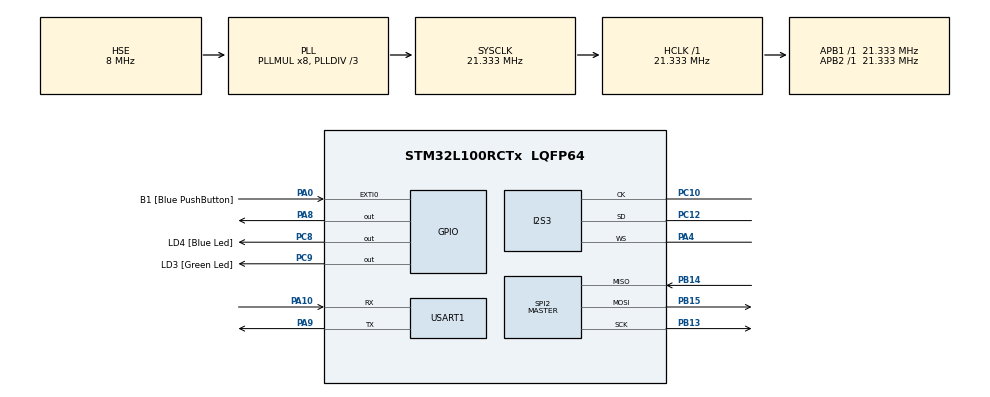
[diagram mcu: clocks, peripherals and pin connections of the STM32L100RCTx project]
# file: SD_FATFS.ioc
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Dma.Request0=USART1_TX
Dma.USART1_TX.0.Direction=DMA_MEMORY_TO_PERIPH
Dma.USART1_TX.0.Instance=DMA1_Channel4
Dma.USART1_TX.0.MemDataAlignment=DMA_MDATAALIGN_BYTE
Dma.USART1_TX.0.MemInc=DMA_MINC_ENABLE
Dma.USART1_TX.0.Mode=DMA_NORMAL
Dma.USART1_TX.0.PeriphDataAlignment=DMA_PDATAALIGN_BYTE
Dma.USART1_TX.0.PeriphInc=DMA_PINC_DISABLE
Dma.USART1_TX.0.Priority=DMA_PRIORITY_LOW
FATFS._MAX_SS=4096
FATFS._USE_LFN=1
I2S3.AudioFreq=I2S_AUDIOFREQ_44K
I2S3.ErrorAudioFreq=1.0 %
I2S3.FullDuplexMode=I2S_FULLDUPLEXMODE_DISABLE
I2S3.Instance=SPI$Index
I2S3.RealAudioFreq=44.444 KHz
I2S3.VirtualMode=I2S_MODE_MASTER
Mcu.Family=STM32L1
Mcu.Name=STM32L100RCTx
Mcu.Package=LQFP64
NVIC.DMA1_Channel4_IRQn=true\:0\:0\:false\:false\:true\:false
NVIC.PriorityGroup=NVIC_PRIORITYGROUP_0
NVIC.TIM2_IRQn=true\:0\:0\:false\:false\:true\:true
NVIC.USART1_IRQn=true\:0\:0\:false\:false\:true\:true
PA0-WKUP1.GPIO_Label=B1 [Blue PushButton]
PA0-WKUP1.GPIO_ModeDefaultEXTI=GPIO_MODE_EVT_RISING
PA0-WKUP1.Signal=GPXTI0
PA10.Mode=Asynchronous
PA10.Signal=USART1_RX
PA13.GPIO_Label=SWDIO
PA13.Mode=Serial_Wire
PA13.Signal=SYS_JTMS-SWDIO
PA14.GPIO_Label=SWCLK
PA14.Mode=Serial_Wire
PA14.Signal=SYS_JTCK-SWCLK
PA4.Mode=Half_Duplex_Master
PA4.Signal=I2S3_WS
PA8.GPIO_Speed=GPIO_SPEED_FREQ_HIGH
PA8.Signal=GPIO_Output
PA9.Mode=Asynchronous
PA9.Signal=USART1_TX
PB13.Mode=Full_Duplex_Master
PB13.Signal=SPI2_SCK
PB14.Mode=Full_Duplex_Master
PB14.Signal=SPI2_MISO
PB15.Mode=Full_Duplex_Master
PB15.Signal=SPI2_MOSI
PB3.GPIO_Label=SWO
PB3.Signal=SYS_JTDO-TRACESWO
PC10.Mode=Half_Duplex_Master
PC10.Signal=I2S3_CK
PC12.Mode=Half_Duplex_Master
PC12.Signal=I2S3_SD
PC14-OSC32_IN.GPIO_Label=PC14-OSC32_IN
PC14-OSC32_IN.Signal=RCC_OSC32_IN
PC15-OSC32_OUT.GPIO_Label=PC15-OSC32_OUT
PC15-OSC32_OUT.Signal=RCC_OSC32_OUT
PC8.GPIO_Label=LD4 [Blue Led]
PC8.Signal=GPIO_Output
PC9.GPIO_Label=LD3 [Green Led]
PC9.Signal=GPIO_Output
PH0-OSC_IN.GPIO_Label=PH0-OSC_IN
PH0-OSC_IN.Mode=HSE-External-Clock-Source
PH0-OSC_IN.Signal=RCC_OSC_IN
PH1-OSC_OUT.GPIO_Label=PH1-OSC_OUT
PH1-OSC_OUT.Signal=RCC_OSC_OUT
ProjectManager.HeapSize=0x200
ProjectManager.StackSize=0x400
ProjectManager.TargetToolchain=SW4STM32
RCC.48MHZClocksFreq_Value=32000000
RCC.AHBFreq_Value=21333333.333333332
RCC.APB1Freq_Value=21333333.333333332
RCC.APB1TimFreq_Value=21333333.333333332
RCC.APB2Freq_Value=21333333.333333332
RCC.APB2TimFreq_Value=21333333.333333332
RCC.HCLKFreq_Value=21333333.333333332
RCC.HSE_VALUE=8000000
RCC.HSI_VALUE=16000000
RCC.LSEState=RCC_LSE_ON
RCC.LSE_VALUE=32768
RCC.MSI_VALUE=2097000
RCC.PLLDIV=RCC_PLL_DIV3
RCC.PLLMUL=RCC_PLL_MUL8
RCC.PLLSourceVirtual=RCC_PLLSOURCE_HSE
RCC.RTCClockSelectionVirtual=RCC_RTCCLKSOURCE_LSE
RCC.SYSCLKFreq_VALUE=21333333.333333332
RCC.SYSCLKSource=RCC_SYSCLKSOURCE_PLLCLK
RCC.USBOutput=48000000
RCC.VCOOutputFreq_Value=64000000
SPI2.BaudRatePrescaler=SPI_BAUDRATEPRESCALER_2
SPI2.CalculateBaudRate=10.666666 MBits/s
SPI2.Direction=SPI_DIRECTION_2LINES
SPI2.Mode=SPI_MODE_MASTER
SPI2.VirtualType=VM_MASTER
TIM2.Period=10
TIM2.Prescaler=39999
USART1.VirtualMode=VM_ASYNC
VP_FATFS_VS_Generic.Mode=User_defined
VP_TIM2_VS_ClockSourceINT.Mode=Internal
board=32L100CDISCOVERY

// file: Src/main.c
/* USER CODE BEGIN Header */
/**
 ******************************************************************************
 * @file           : main.c
 * @brief          : Main program body
 ******************************************************************************
 * This notice applies to any and all portions of this file
 * that are not between comment pairs USER CODE BEGIN and
 * USER CODE END. Other portions of this file, whether
 * inserted by the user or by software development tools
 * are owned by their respective copyright owners.
 *
 * Copyright (c) 2018 STMicroelectronics International N.V.
 * All rights reserved.
 *
 * Redistribution and use in source and binary forms, with or without
 * modification, are permitted, provided that the following conditions are met:
 *
 * 1. Redistribution of source code must retain the above copyright notice,
 *    this list of conditions and the following disclaimer.
 * 2. Redistributions in binary form must reproduce the above copyright notice,
 *    this list of conditions and the following disclaimer in the documentation
 *    and/or other materials provided with the distribution.
 * 3. Neither the name of STMicroelectronics nor the names of other
 *    contributors to this software may be used to endorse or promote products
 *    derived from this software without specific written permission.
 * 4. This software, including modifications and/or derivative works of this
 *    software, must execute solely and exclusively on microcontroller or
 *    microprocessor devices manufactured by or for STMicroelectronics.
 * 5. Redistribution and use of this software other than as permitted under
 *    this license is void and will automatically terminate your rights under
 *    this license.
 *
 * THIS SOFTWARE IS PROVIDED BY STMICROELECTRONICS AND CONTRIBUTORS "AS IS"
 * AND ANY EXPRESS, IMPLIED OR STATUTORY WARRANTIES, INCLUDING, BUT NOT
 * LIMITED TO, THE IMPLIED WARRANTIES OF MERCHANTABILITY, FITNESS FOR A
 * PARTICULAR PURPOSE AND NON-INFRINGEMENT OF THIRD PARTY INTELLECTUAL PROPERTY
 * RIGHTS ARE DISCLAIMED TO THE FULLEST EXTENT PERMITTED BY LAW. IN NO EVENT
 * SHALL STMICROELECTRONICS OR CONTRIBUTORS BE LIABLE FOR ANY DIRECT, INDIRECT,
 * INCIDENTAL, SPECIAL, EXEMPLARY, OR CONSEQUENTIAL DAMAGES (INCLUDING, BUT NOT
 * LIMITED TO, PROCUREMENT OF SUBSTITUTE GOODS OR SERVICES; LOSS OF USE, DATA,
 * OR PROFITS; OR BUSINESS INTERRUPTION) HOWEVER CAUSED AND ON ANY THEORY OF
 * LIABILITY, WHETHER IN CONTRACT, STRICT LIABILITY, OR TORT (INCLUDING
 * NEGLIGENCE OR OTHERWISE) ARISING IN ANY WAY OUT OF THE USE OF THIS SOFTWARE,
 * EVEN IF ADVISED OF THE POSSIBILITY OF SUCH DAMAGE.
 *
 ******************************************************************************
 */
/* USER CODE END Header */

#include "main.h"
#include "fatfs.h"

/* USER CODE BEGIN Includes */
#include "sd.h"
/* USER CODE END Includes */

I2S_HandleTypeDef hi2s3;

SPI_HandleTypeDef hspi2;

TIM_HandleTypeDef htim2;

UART_HandleTypeDef huart1;
DMA_HandleTypeDef hdma_usart1_tx;

/* USER CODE BEGIN PV */
volatile uint16_t Timer1 = 0;
uint8_t sect[512];
extern char str1[60];
uint32_t byteswritten, bytesread;
uint8_t result;
extern char USER_Path[4]; /* logical drive path */
FATFS SDFatFs;
FATFS *fs;
//FIL MyFile;
/* USER CODE END PV */

void SystemClock_Config(void);
static void MX_GPIO_Init(void);
static void MX_DMA_Init(void);
static void MX_SPI2_Init(void);
static void MX_USART1_UART_Init(void);
static void MX_TIM2_Init(void);
static void MX_I2S3_Init(void);

int main(void) {

	/* MCU Configuration--------------------------------------------------------*/

	/* Reset of all peripherals, Initializes the Flash interface and the Systick. */
	HAL_Init();

	/* Configure the system clock */
	SystemClock_Config();

	/* Initialize all configured peripherals */
	MX_GPIO_Init();
	MX_DMA_Init();
	MX_SPI2_Init();
	MX_FATFS_Init();
	MX_USART1_UART_Init();
	MX_TIM2_Init();
	MX_I2S3_Init();
	/* USER CODE BEGIN 2 */
	HAL_TIM_Base_Start_IT(&htim2);
//  sd_init();
	disk_initialize(SDFatFs.drv);
	/* USER CODE END 2 */

	/* Infinite loop */
	while (1) {

		/* USER CODE BEGIN 3 */
//	  HAL_UART_Transmit_DMA(&huart1, "SD", 3);
	}
	/* USER CODE END 3 */
}

void SystemClock_Config(void) {
	RCC_OscInitTypeDef RCC_OscInitStruct = { 0 };
	RCC_ClkInitTypeDef RCC_ClkInitStruct = { 0 };

	/**Configure the main internal regulator output voltage
	 */
	__HAL_PWR_VOLTAGESCALING_CONFIG(PWR_REGULATOR_VOLTAGE_SCALE1);
	/**Initializes the CPU, AHB and APB busses clocks
	 */
	RCC_OscInitStruct.OscillatorType = RCC_OSCILLATORTYPE_HSE;
	RCC_OscInitStruct.HSEState = RCC_HSE_BYPASS;
	RCC_OscInitStruct.PLL.PLLState = RCC_PLL_ON;
	RCC_OscInitStruct.PLL.PLLSource = RCC_PLLSOURCE_HSE;
	RCC_OscInitStruct.PLL.PLLMUL = RCC_PLL_MUL8;
	RCC_OscInitStruct.PLL.PLLDIV = RCC_PLL_DIV3;
	if (HAL_RCC_OscConfig(&RCC_OscInitStruct) != HAL_OK) {
		Error_Handler();
	}
	/**Initializes the CPU, AHB and APB busses clocks
	 */
	RCC_ClkInitStruct.ClockType = RCC_CLOCKTYPE_HCLK | RCC_CLOCKTYPE_SYSCLK
			| RCC_CLOCKTYPE_PCLK1 | RCC_CLOCKTYPE_PCLK2;
	RCC_ClkInitStruct.SYSCLKSource = RCC_SYSCLKSOURCE_PLLCLK;
	RCC_ClkInitStruct.AHBCLKDivider = RCC_SYSCLK_DIV1;
	RCC_ClkInitStruct.APB1CLKDivider = RCC_HCLK_DIV1;
	RCC_ClkInitStruct.APB2CLKDivider = RCC_HCLK_DIV1;

	if (HAL_RCC_ClockConfig(&RCC_ClkInitStruct, FLASH_LATENCY_1) != HAL_OK) {
		Error_Handler();
	}
}

static void MX_I2S3_Init(void) {

	hi2s3.Instance = SPI3;
	hi2s3.Init.Mode = I2S_MODE_MASTER_TX;
	hi2s3.Init.Standard = I2S_STANDARD_PHILIPS;
	hi2s3.Init.DataFormat = I2S_DATAFORMAT_16B;
	hi2s3.Init.MCLKOutput = I2S_MCLKOUTPUT_DISABLE;
	hi2s3.Init.AudioFreq = I2S_AUDIOFREQ_44K;
	hi2s3.Init.CPOL = I2S_CPOL_LOW;
	if (HAL_I2S_Init(&hi2s3) != HAL_OK) {
		Error_Handler();
	}

}

static void MX_SPI2_Init(void) {

	/* SPI2 parameter configuration*/
	hspi2.Instance = SPI2;
	hspi2.Init.Mode = SPI_MODE_MASTER;
	hspi2.Init.Direction = SPI_DIRECTION_2LINES;
	hspi2.Init.DataSize = SPI_DATASIZE_8BIT;
	hspi2.Init.CLKPolarity = SPI_POLARITY_LOW;
	hspi2.Init.CLKPhase = SPI_PHASE_1EDGE;
	hspi2.Init.NSS = SPI_NSS_SOFT;
	hspi2.Init.BaudRatePrescaler = SPI_BAUDRATEPRESCALER_2;
	hspi2.Init.FirstBit = SPI_FIRSTBIT_MSB;
	hspi2.Init.TIMode = SPI_TIMODE_DISABLE;
	hspi2.Init.CRCCalculation = SPI_CRCCALCULATION_DISABLE;
	hspi2.Init.CRCPolynomial = 10;
	if (HAL_SPI_Init(&hspi2) != HAL_OK) {
		Error_Handler();
	}

}

static void MX_TIM2_Init(void) {

	TIM_ClockConfigTypeDef sClockSourceConfig = { 0 };
	TIM_MasterConfigTypeDef sMasterConfig = { 0 };

	htim2.Instance = TIM2;
	htim2.Init.Prescaler = 39999;
	htim2.Init.CounterMode = TIM_COUNTERMODE_UP;
	htim2.Init.Period = 10;
	htim2.Init.ClockDivision = TIM_CLOCKDIVISION_DIV1;
	if (HAL_TIM_Base_Init(&htim2) != HAL_OK) {
		Error_Handler();
	}
	sClockSourceConfig.ClockSource = TIM_CLOCKSOURCE_INTERNAL;
	if (HAL_TIM_ConfigClockSource(&htim2, &sClockSourceConfig) != HAL_OK) {
		Error_Handler();
	}
	sMasterConfig.MasterOutputTrigger = TIM_TRGO_RESET;
	sMasterConfig.MasterSlaveMode = TIM_MASTERSLAVEMODE_DISABLE;
	if (HAL_TIMEx_MasterConfigSynchronization(&htim2, &sMasterConfig)
			!= HAL_OK) {
		Error_Handler();
	}

}

static void MX_USART1_UART_Init(void) {

	huart1.Instance = USART1;
	huart1.Init.BaudRate = 115200;
	huart1.Init.WordLength = UART_WORDLENGTH_8B;
	huart1.Init.StopBits = UART_STOPBITS_1;
	huart1.Init.Parity = UART_PARITY_NONE;
	huart1.Init.Mode = UART_MODE_TX_RX;
	huart1.Init.HwFlowCtl = UART_HWCONTROL_NONE;
	huart1.Init.OverSampling = UART_OVERSAMPLING_16;
	if (HAL_UART_Init(&huart1) != HAL_OK) {
		Error_Handler();
	}

}

static void MX_DMA_Init(void) {
	/* DMA controller clock enable */
	__HAL_RCC_DMA1_CLK_ENABLE()
	;

	/* DMA interrupt init */
	/* DMA1_Channel4_IRQn interrupt configuration */
	HAL_NVIC_SetPriority(DMA1_Channel4_IRQn, 0, 0);
	HAL_NVIC_EnableIRQ(DMA1_Channel4_IRQn);

}

static void MX_GPIO_Init(void) {
	GPIO_InitTypeDef GPIO_InitStruct = { 0 };

	/* GPIO Ports Clock Enable */
	__HAL_RCC_GPIOC_CLK_ENABLE()
	;
	__HAL_RCC_GPIOH_CLK_ENABLE()
	;
	__HAL_RCC_GPIOA_CLK_ENABLE()
	;
	__HAL_RCC_GPIOB_CLK_ENABLE()
	;

	/*Configure GPIO pin Output Level */
	HAL_GPIO_WritePin(GPIOC, LD4_Pin | LD3_Pin, GPIO_PIN_RESET);

	/*Configure GPIO pin Output Level */
	HAL_GPIO_WritePin(GPIOA, GPIO_PIN_8, GPIO_PIN_RESET);

	/*Configure GPIO pin : B1_Pin */
	GPIO_InitStruct.Pin = B1_Pin;
	GPIO_InitStruct.Mode = GPIO_MODE_EVT_RISING;
	GPIO_InitStruct.Pull = GPIO_NOPULL;
	HAL_GPIO_Init(B1_GPIO_Port, &GPIO_InitStruct);

	/*Configure GPIO pins : LD4_Pin LD3_Pin */
	GPIO_InitStruct.Pin = LD4_Pin | LD3_Pin;
	GPIO_InitStruct.Mode = GPIO_MODE_OUTPUT_PP;
	GPIO_InitStruct.Pull = GPIO_NOPULL;
	GPIO_InitStruct.Speed = GPIO_SPEED_FREQ_LOW;
	HAL_GPIO_Init(GPIOC, &GPIO_InitStruct);

	/*Configure GPIO pin : PA8 */
	GPIO_InitStruct.Pin = GPIO_PIN_8;
	GPIO_InitStruct.Mode = GPIO_MODE_OUTPUT_PP;
	GPIO_InitStruct.Pull = GPIO_NOPULL;
	GPIO_InitStruct.Speed = GPIO_SPEED_FREQ_HIGH;
	HAL_GPIO_Init(GPIOA, &GPIO_InitStruct);

}

/* USER CODE BEGIN 4 */
void HAL_TIM_PeriodElapsedCallback(TIM_HandleTypeDef *htim) {
	if (htim == &htim2) {
		Timer1++;
	}
}

/* USER CODE END 4 */

void Error_Handler(void) {
}

/************************ (C) COPYRIGHT STMicroelectronics *****END OF FILE****/
